# ATtiny1616 device description
Architecture: AVR8X; Family: AVR TINY
Registers are 8-bit, read-write, reset 0x0 unless marked. A register's access mark holds for its fields unless they carry their own. Offsets are from the block's base; [hi:lo] are bit positions; 'fields as' and 'values as' point back to an identical list.

## CLKCTRL — Clock controller
Instances: CLKCTRL 0x0060
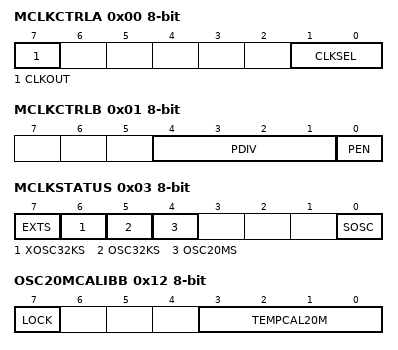
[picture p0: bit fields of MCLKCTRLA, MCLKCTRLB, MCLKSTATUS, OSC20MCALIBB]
0x00 MCLKCTRLA — MCLK Control A
  [7] CLKOUT — System clock out
  [1:0] CLKSEL — clock select
    0=OSC20M (20MHz internal oscillator); 1=OSCULP32K (32KHz internal Ultra Low Power oscillator); 2=XOSC32K (32.768kHz external crystal oscillator); 3=EXTCLK (External clock)
0x01 MCLKCTRLB — MCLK Control B
  [4:1] PDIV — Prescaler division
    0=2X; 1=4X; 2=8X; 3=16X; 4=32X; 5=64X; 8=6X; 9=10X; 10=12X; 11=24X; 12=48X
  [0] PEN — Prescaler enable
0x02 MCLKLOCK reset not defined
  [0] LOCKEN — lock ebable
0x03 MCLKSTATUS ro
  [7] EXTS — External Clock status
  [6] XOSC32KS — 32.768 kHz Crystal Oscillator status
  [5] OSC32KS — 32KHz oscillator status
  [4] OSC20MS — 20MHz oscillator status
  [0] SOSC — System Oscillator changing
0x10 OSC20MCTRLA reset not defined — OSC20M Control A
  [1] RUNSTDBY — Run standby
0x11 OSC20MCALIBA — OSC20M Calibration A
  [5:0] CAL20M — Calibration
0x12 OSC20MCALIBB — OSC20M Calibration B
  [7] LOCK
  [3:0] TEMPCAL20M — Oscillator temperature coefficient
0x18 OSC32KCTRLA — OSC32K Control A
  [1] RUNSTDBY — Run standby
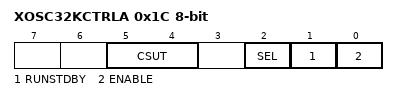
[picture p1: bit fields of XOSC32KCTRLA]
0x1C XOSC32KCTRLA — XOSC32K Control A
  [5:4] CSUT — Crystal startup time
    0=1K (1K cycles); 1=16K (16K cycles); 2=32K (32K cycles); 3=64K (64K cycles)
  [2] SEL — Select
  [1] RUNSTDBY — Run standby
  [0] ENABLE

## CPU
Instances: CPU 0x0030
0x04 CCP — Configuration Change Protection
  [7:0] CCP — CCP signature
    157=SPM (SPM Instruction Protection); 216=IOREG (IO Register Protection)
0x0D SPL reset not defined — Stack Pointer Low
0x0E SPH reset not defined — Stack Pointer High
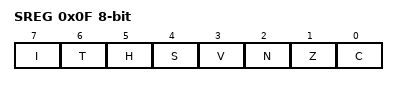
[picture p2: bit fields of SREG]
0x0F SREG — Status Register
  [7] I — Global Interrupt Enable Flag
  [6] T — Transfer Bit
  [5] H — Half Carry Flag
  [4] S — N Exclusive Or V Flag
  [3] V — Two's Complement Overflow Flag
  [2] N — Negative Flag
  [1] Z — Zero Flag
  [0] C — Carry Flag

## CPUINT — Interrupt Controller
Instances: CPUINT 0x0110
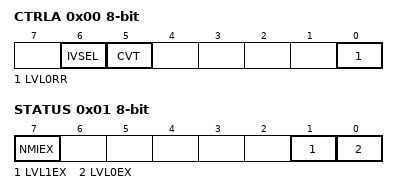
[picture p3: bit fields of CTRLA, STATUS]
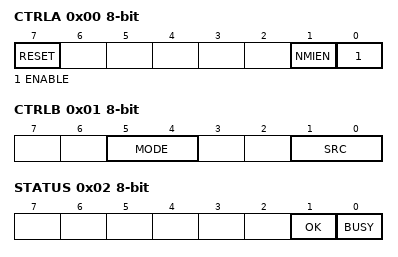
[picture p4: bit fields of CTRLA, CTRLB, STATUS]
0x00 CTRLA — Control A
  [6] IVSEL — Interrupt Vector Select
  [5] CVT — Compact Vector Table
  [0] LVL0RR — Round-robin Scheduling Enable
0x01 STATUS
  [7] NMIEX ro — Non-maskable Interrupt Executing
  [1] LVL1EX ro — Level 1 Interrupt Executing
  [0] LVL0EX ro — Level 0 Interrupt Executing
0x02 LVL0PRI — Interrupt Level 0 Priority
  [7:0] LVL0PRI — Interrupt Level Priority
0x03 LVL1VEC — Interrupt Level 1 Priority Vector
  [7:0] LVL1VEC — Interrupt Vector with High Priority

## CRCSCAN
Instances: CRCSCAN 0x0120
0x00 CTRLA — Control A
  [7] RESET — Reset CRC scan
  [1] NMIEN — Enable NMI Trigger
  [0] ENABLE — Enable CRC scan
0x01 CTRLB — Control B
  [5:4] MODE — CRC Flash Access Mode
    0=PRIORITY (Priority to flash); 2=BACKGROUND (Lowest priority to flash); 3=CONTINUOUS (Continuous checks in background)
  [1:0] SRC — CRC Source
    0=FLASH (CRC on entire flash); 1=APPLICATION (CRC on boot and appl section of flash); 2=BOOT (CRC on boot section of flash)
0x02 STATUS ro
  [1] OK — CRC Ok
  [0] BUSY — CRC Busy

## DAC — Digital to Analog Converter
Instances: DAC0 0x06A0, DAC1 0x06A8, DAC2 0x06B0
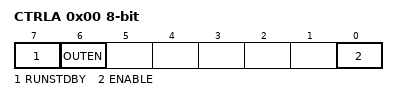
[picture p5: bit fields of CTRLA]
0x00 CTRLA — Control Register A
  [7] RUNSTDBY — Run in Standby Mode
  [6] OUTEN — Output Buffer Enable
  [0] ENABLE — DAC Enable
0x01 DATA reset not defined

## FUSE — Fuses
Instances: FUSE 0x1280
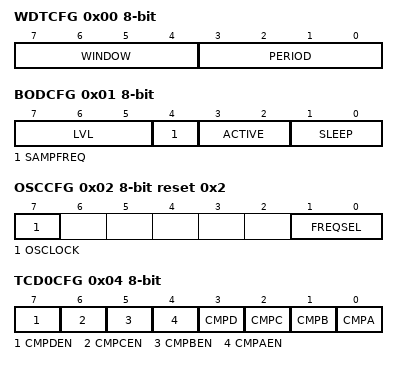
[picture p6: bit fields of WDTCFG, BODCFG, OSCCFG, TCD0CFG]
0x00 WDTCFG — Watchdog Configuration
  [7:4] WINDOW — Watchdog Window Timeout Period
    0=OFF; 1=8CLK (8 cycles (8ms)); 2=16CLK (16 cycles (16ms)); 3=32CLK (32 cycles (32ms)); 4=64CLK (64 cycles (64ms)); 5=128CLK (128 cycles (0.128s)); 6=256CLK (256 cycles (0.256s)); 7=512CLK (512 cycles (0.512s)); 8=1KCLK (1K cycles (1.0s)); 9=2KCLK (2K cycles (2.0s)); 10=4KCLK (4K cycles (4.1s)); 11=8KCLK (8K cycles (8.2s))
  [3:0] PERIOD — Watchdog Timeout Period
    values as WINDOW
0x01 BODCFG — BOD Configuration
  [7:5] LVL — BOD Level
    0=BODLEVEL0 (1.8 V); 2=BODLEVEL2 (2.6 V); 7=BODLEVEL7 (4.2 V)
  [4] SAMPFREQ — BOD Sample Frequency
    0=1KHZ (1kHz sampling frequency); 1=125HZ (125Hz sampling frequency)
  [3:2] ACTIVE — BOD Operation in Active Mode
    0=DIS (Disabled); 1=ENABLED; 2=SAMPLED; 3=ENWAKE (Enabled with wake-up halted until BOD is ready)
  [1:0] SLEEP — BOD Operation in Sleep Mode
    0=DIS (Disabled); 1=ENABLED; 2=SAMPLED
0x02 OSCCFG reset 0x2 — Oscillator Configuration
  [7] OSCLOCK — Oscillator Lock
  [1:0] FREQSEL — Frequency Select
    1=16MHZ; 2=20MHZ
0x04 TCD0CFG — TCD0 Configuration
  [7] CMPDEN — Compare D Output Enable
  [6] CMPCEN — Compare C Output Enable
  [5] CMPBEN — Compare B Output Enable
  [4] CMPAEN — Compare A Output Enable
  [3] CMPD — Compare D Default Output Value
  [2] CMPC — Compare C Default Output Value
  [1] CMPB — Compare B Default Output Value
  [0] CMPA — Compare A Default Output Value
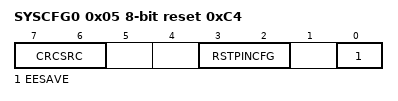
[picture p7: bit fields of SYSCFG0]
0x05 SYSCFG0 reset 0xC4 — System Configuration 0
  [7:6] CRCSRC — CRC Source
    0=FLASH (The CRC is performed on the entire Flash (boot, application code and application data section).); 1=BOOT (The CRC is performed on the boot section of Flash); 2=BOOTAPP (The CRC is performed on the boot and application code section of Flash); 3=NOCRC (Disable CRC.)
  [3:2] RSTPINCFG — Reset Pin Configuration
    0=GPIO (GPIO mode); 1=UPDI (UPDI mode); 2=RST (Reset mode)
  [0] EESAVE — EEPROM Save
0x06 SYSCFG1 reset 0x7 — System Configuration 1
  [2:0] SUT — Startup Time
    0=0MS; 1=1MS; 2=2MS; 3=4MS; 4=8MS; 5=16MS; 6=32MS; 7=64MS
0x07 APPEND — Application Code Section End
0x08 BOOTEND — Boot Section End
